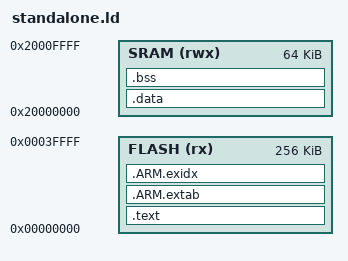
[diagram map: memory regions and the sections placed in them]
ENTRY(ResetISR)
MEMORY
{
    FLASH (rx) : ORIGIN = 0x00000000, LENGTH = 256K
    SRAM (rwx) : ORIGIN = 0x20000000, LENGTH = 64K
}

SECTIONS
{
        .text :
        {
                _text = .;
                KEEP(*(.isr_vector))
                *(.text*)

                KEEP(*(.init))
                KEEP(*(.fini))

                /* .ctors */
                *crtbegin.o(.ctors)
                *crtbegin?.o(.ctors)
                *(EXCLUDE_FILE(*crtend?.o *crtend.o) .ctors)
                *(SORT(.ctors.*))
                *(.ctors)

                /* .dtors */
                *crtbegin.o(.dtors)
                *crtbegin?.o(.dtors)
                *(EXCLUDE_FILE(*crtend?.o *crtend.o) .dtors)
                *(SORT(.dtors.*))
                *(.dtors)

                *(.rodata*)

                KEEP(*(.eh_frame*))
        } > FLASH

        .ARM.extab :
        {
                *(.ARM.extab* .gnu.linkonce.armextab.*)
        } > FLASH

        __exidx_start = .;
        .ARM.exidx :
        {
                *(.ARM.exidx* .gnu.linkonce.armexidx.*)
        } > FLASH
        __exidx_end = .;

        . = ALIGN(4);
        _etext = .;

        .data : AT (_etext)
        {
                _data = .;
                __data_start__ = .;
                *(.ramfunc*)
                . = ALIGN(4);
                *(vtable)
                *(.data*)

                . = ALIGN(4);
                PROVIDE_HIDDEN (__preinit_array_start = .);
                KEEP(*(.preinit_array))
                PROVIDE_HIDDEN (__preinit_array_end = .);

                . = ALIGN(4);
                PROVIDE_HIDDEN (__init_array_start = .);
                KEEP(*(SORT(.init_array.*)))
                KEEP(*(.init_array))
                PROVIDE_HIDDEN (__init_array_end = .);

                . = ALIGN(4);
                PROVIDE_HIDDEN (__fini_array_start = .);
                KEEP(*(SORT(.fini_array.*)))
                KEEP(*(.fini_array))
                PROVIDE_HIDDEN (__fini_array_end = .);

                KEEP(*(.jcr*))
                . = ALIGN(4);
                __data_end__ = .;
                _edata = .;
        } > SRAM

        .bss :
        {
                . = ALIGN(4);
                _bss = .;
                __bss_start__ = .;
                *(.bss*)
                *(COMMON)
                . = ALIGN(4);
                __bss_end__ = .;
                _ebss = .;
        } > SRAM
}
